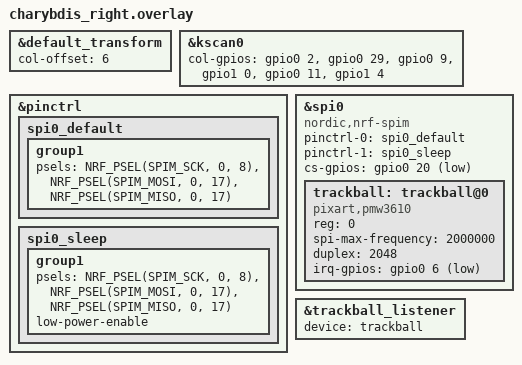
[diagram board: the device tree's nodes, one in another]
#include "charybdis.dtsi"
#include <dt-bindings/pinctrl/nrf-pinctrl.h>
#include <dt-bindings/input/input-event-codes.h>

&default_transform {
    col-offset = <6>;
};

&kscan0 {
    col-gpios =
        <&gpio0 2 (GPIO_ACTIVE_HIGH | GPIO_PULL_DOWN)>,
        <&gpio0 29 (GPIO_ACTIVE_HIGH | GPIO_PULL_DOWN)>,
        <&gpio0 9 (GPIO_ACTIVE_HIGH | GPIO_PULL_DOWN)>,
        <&gpio1 0 (GPIO_ACTIVE_HIGH | GPIO_PULL_DOWN)>,
        <&gpio0 11 (GPIO_ACTIVE_HIGH | GPIO_PULL_DOWN)>,
        <&gpio1 4 (GPIO_ACTIVE_HIGH | GPIO_PULL_DOWN)>;
};

&pinctrl {
    spi0_default: spi0_default {
        group1 {
            psels =
                <NRF_PSEL(SPIM_SCK, 0, 8)>,
                <NRF_PSEL(SPIM_MOSI, 0, 17)>,
                <NRF_PSEL(SPIM_MISO, 0, 17)>;
        };
    };

    spi0_sleep: spi0_sleep {
        group1 {
            psels =
                <NRF_PSEL(SPIM_SCK, 0, 8)>,
                <NRF_PSEL(SPIM_MOSI, 0, 17)>,
                <NRF_PSEL(SPIM_MISO, 0, 17)>;
            low-power-enable;
        };
    };
};

&spi0 {
    compatible = "nordic,nrf-spim";
    status = "okay";
    pinctrl-0 = <&spi0_default>;
    pinctrl-1 = <&spi0_sleep>;
    pinctrl-names = "default", "sleep";
    cs-gpios = <&gpio0 20 GPIO_ACTIVE_LOW>;

    trackball: trackball@0 {
        compatible = "pixart,pmw3610";
        status = "okay";
        reg = <0>;
        spi-max-frequency = <2000000>;
        duplex = <2048>;
        irq-gpios = <&gpio0 6 (GPIO_ACTIVE_LOW | GPIO_PULL_UP)>;
};
};

&trackball_listener {
    status = "okay";
    device = <&trackball>;
};
